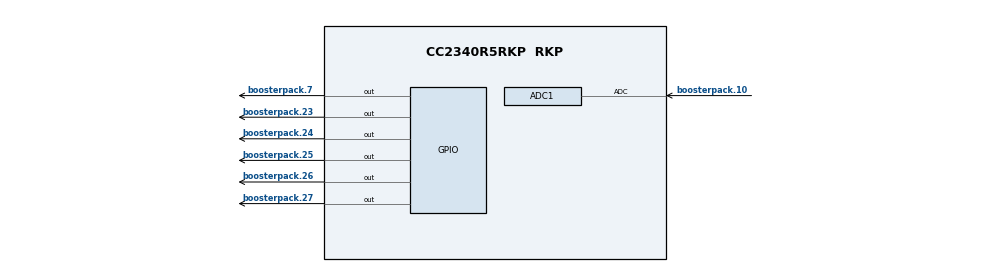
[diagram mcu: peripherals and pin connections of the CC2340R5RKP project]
/**
 * @cliArgs --board "/ti/boards/LP_EM_CC2340R5" --device "CC2340R5RKP" --part "Default" --package "RKP" --rtos "freertos" --product "simplelink_lowpower_f3_sdk@9.11.00.18"
 * @versions {"tool":"1.23.2+4156"}
 */

/**
 * Import the modules used in this configuration.
 */
const FreeRTOS  = scripting.addModule("/freertos/FreeRTOS");
const CCFG      = scripting.addModule("/ti/devices/CCFG");
const custom    = scripting.addModule("/ti/devices/radioconfig/custom");
const rfdesign  = scripting.addModule("/ti/devices/radioconfig/rfdesign");
const ADC       = scripting.addModule("/ti/drivers/ADC", {}, false);
const ADC1      = ADC.addInstance();
const ADCBuf    = scripting.addModule("/ti/drivers/ADCBuf", {}, false);
const ADCBuf1   = ADCBuf.addInstance();
const GPIO      = scripting.addModule("/ti/drivers/GPIO");
const GPIO3     = GPIO.addInstance();
const GPIO4     = GPIO.addInstance();
const GPIO5     = GPIO.addInstance();
const GPIO6     = GPIO.addInstance();
const GPIO7     = GPIO.addInstance();
const GPIO8     = GPIO.addInstance();
const GPIO9     = GPIO.addInstance();
const GPIO10    = GPIO.addInstance();
const GPIO11    = GPIO.addInstance();
const GPIO12    = GPIO.addInstance();
const LGPTimer  = scripting.addModule("/ti/drivers/LGPTimer", {}, false);
const LGPTimer1 = LGPTimer.addInstance();
const Power     = scripting.addModule("/ti/drivers/Power");
const RCL       = scripting.addModule("/ti/drivers/RCL");
const Settings  = scripting.addModule("/ti/posix/freertos/Settings");

/**
 * Write custom configuration values to the imported modules.
 */
CCFG.ccfgTemplate.$name = "ti_devices_CCFG_CCFGCC23X0Template0";

custom.ble                                                      = ["ble_gen"];
custom.radioConfigble_gen.$name                                 = "RF_BLE_Setting";
custom.radioConfigble_gen.codeExportConfig.$name                = "ti_devices_radioconfig_code_export_param0";
custom.radioConfigble_gen.codeExportConfig.registerFieldDefines = "PBE_GENERIC_RAM_LENCFG_LENPOS,PBE_GENERIC_RAM_LENCFG_NUMLENBITS";

ADC1.$name                         = "CONFIG_ADC_VSENB";
ADC1.adcChannel.adc.adcPin.$assign = "boosterpack.10";

ADCBuf1.$name                             = "CONFIG_ADCBUF_VSENA";
ADCBuf1.adcChannels[0].$name              = "CONFIG_ADC_CHANNEL_0";
ADCBuf1.adcChannels[0].adc.adcPin.$assign = "boosterpack.9";

GPIO3.$hardware = system.deviceData.board.components.LED_RED;
GPIO3.$name     = "CONFIG_GPIO_RLED";

GPIO4.$hardware = system.deviceData.board.components.LED_GREEN;
GPIO4.$name     = "CONFIG_GPIO_GLED";

GPIO5.$name           = "CONFIG_GPIO_nSLEEP";
GPIO5.mode            = "Output";
GPIO5.gpioPin.$assign = "boosterpack.25";

GPIO6.$name           = "CONFIG_GPIO_AOUT1";
GPIO6.mode            = "Output";
GPIO6.gpioPin.$assign = "boosterpack.23";

GPIO7.$name           = "CONFIG_GPIO_AOUT2";
GPIO7.mode            = "Output";
GPIO7.gpioPin.$assign = "boosterpack.26";

GPIO8.$name           = "CONFIG_GPIO_BOUT1";
GPIO8.mode            = "Output";
GPIO8.gpioPin.$assign = "boosterpack.27";

GPIO9.$name           = "CONFIG_GPIO_BOUT2";
GPIO9.mode            = "Output";
GPIO9.gpioPin.$assign = "boosterpack.24";

GPIO10.$name           = "CONFIG_GPIO_nFAULT";
GPIO10.gpioPin.$assign = "boosterpack.7";

GPIO11.$name     = "CONFIG_GPIO_BTN_RIGHT";
GPIO11.$hardware = system.deviceData.board.components["BTN-2"];

GPIO12.$name     = "CONFIG_GPIO_BTN_LEFT";
GPIO12.$hardware = system.deviceData.board.components["BTN-1"];

LGPTimer1.$name         = "CONFIG_LGPTIMER_0";
LGPTimer1.timer.$assign = "LGPT3";

Power.policyFunction       = "Custom";
Power.policyCustomFunction = "PowerCC23X0_customPolicy";

/**
 * Pinmux solution for unlocked pins/peripherals. This ensures that minor changes to the automatic solver in a future
 * version of the tool will not impact the pinmux you originally saw.  These lines can be completely deleted in order to
 * re-solve from scratch.
 */
ADC1.adcChannel.adc.$suggestSolution        = "ADC";
ADCBuf1.adc.$suggestSolution                = "ADC";
ADCBuf1.adc.dataDmaChannel.$suggestSolution = "DMA_CH3";
ADCBuf1.adcChannels[0].adc.$suggestSolution = "ADC";
GPIO3.gpioPin.$suggestSolution              = "boosterpack.39";
GPIO4.gpioPin.$suggestSolution              = "boosterpack.40";
GPIO11.gpioPin.$suggestSolution             = "boosterpack.12";
GPIO12.gpioPin.$suggestSolution             = "boosterpack.13";
